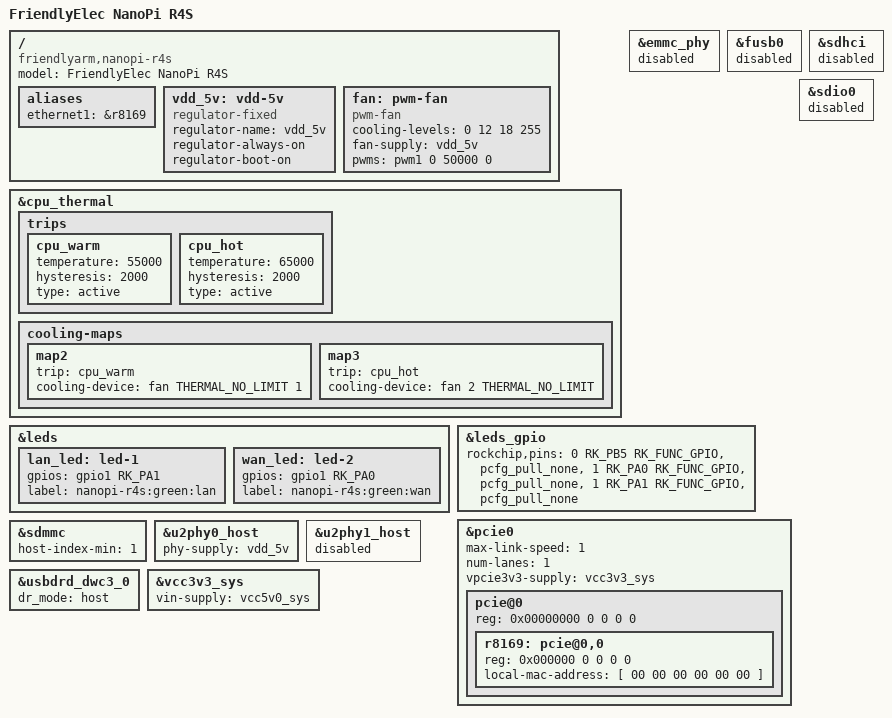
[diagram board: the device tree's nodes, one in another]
// SPDX-License-Identifier: (GPL-2.0+ OR MIT)
/*
 * Copyright (c) 2016 Fuzhou Rockchip Electronics Co., Ltd
 *
 * Copyright (c) 2018 FriendlyElec Computer Tech. Co., Ltd.
 * (http://www.friendlyarm.com)
 *
 * Copyright (c) 2018 Collabora Ltd.
 * Copyright (c) 2019 Arm Ltd.
 * Copyright (C) 2020 Xiaobo <peterwillcn@gmail.com>
 */

/dts-v1/;
#include "rk3399-nanopi4.dtsi"

/ {
	model = "FriendlyElec NanoPi R4S";
	compatible = "friendlyarm,nanopi-r4s", "rockchip,rk3399";

	aliases {
		ethernet1 = &r8169;
	};

	vdd_5v: vdd-5v {
		compatible = "regulator-fixed";
		regulator-name = "vdd_5v";
		regulator-always-on;
		regulator-boot-on;
	};

	fan: pwm-fan {
		compatible = "pwm-fan";
		cooling-levels = <0 12 18 255>;
		#cooling-cells = <2>;
		fan-supply = <&vdd_5v>;
		pwms = <&pwm1 0 50000 0>;
	};
};

&cpu_thermal {
	trips {
		cpu_warm: cpu_warm {
			temperature = <55000>;
			hysteresis = <2000>;
			type = "active";
		};

		cpu_hot: cpu_hot {
			temperature = <65000>;
			hysteresis = <2000>;
			type = "active";
		};
	};

	cooling-maps {
		map2 {
			trip = <&cpu_warm>;
			cooling-device = <&fan THERMAL_NO_LIMIT 1>;
		};

		map3 {
			trip = <&cpu_hot>;
			cooling-device = <&fan 2 THERMAL_NO_LIMIT>;
		};
	};
};

&emmc_phy {
	status = "disabled";
};

&fusb0 {
	status = "disabled";
};

&leds {
	lan_led: led-1 {
		gpios = <&gpio1 RK_PA1 GPIO_ACTIVE_HIGH>;
		label = "nanopi-r4s:green:lan";
	};

	wan_led: led-2 {
		gpios = <&gpio1 RK_PA0 GPIO_ACTIVE_HIGH>;
		label = "nanopi-r4s:green:wan";
	};
};

&leds_gpio {
	rockchip,pins =
		<0 RK_PB5 RK_FUNC_GPIO &pcfg_pull_none>,
		<1 RK_PA0 RK_FUNC_GPIO &pcfg_pull_none>,
		<1 RK_PA1 RK_FUNC_GPIO &pcfg_pull_none>;
};

&pcie0 {
	max-link-speed = <1>;
	num-lanes = <1>;
	vpcie3v3-supply = <&vcc3v3_sys>;

	pcie@0 {
		reg = <0x00000000 0 0 0 0>;
		#address-cells = <3>;
		#size-cells = <2>;

		r8169: pcie@0,0 {
			reg = <0x000000 0 0 0 0>;
			local-mac-address = [ 00 00 00 00 00 00 ];
		};
	};
};

&sdhci {
	status = "disabled";
};

&sdio0 {
	status = "disabled";
};

&sdmmc {
	host-index-min = <1>;
};

&u2phy0_host {
	phy-supply = <&vdd_5v>;
};

&u2phy1_host {
	status = "disabled";
};

&usbdrd_dwc3_0 {
	dr_mode = "host";
};

&vcc3v3_sys {
	vin-supply = <&vcc5v0_sys>;
};
